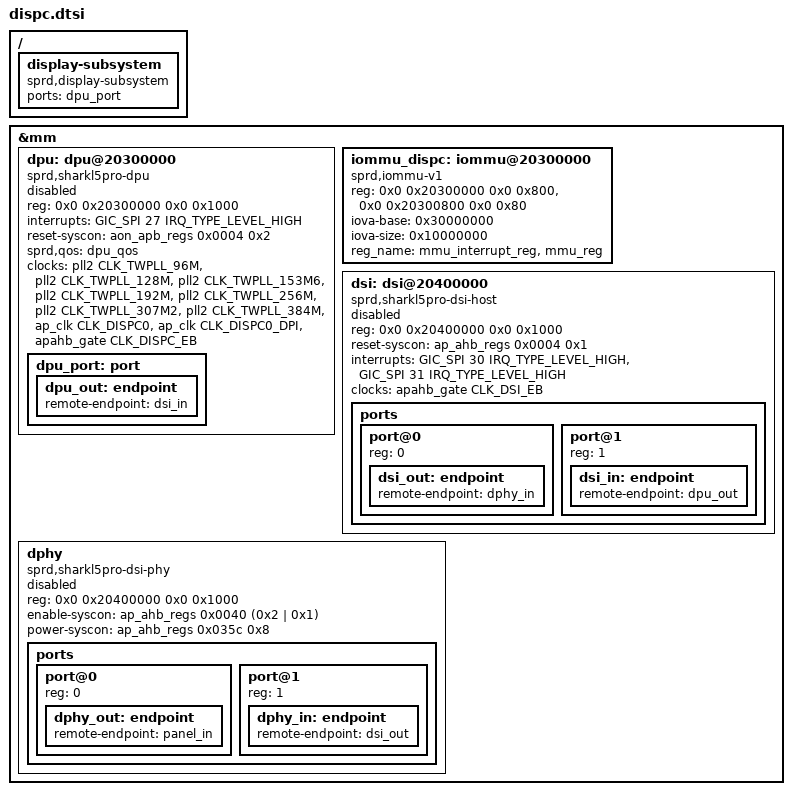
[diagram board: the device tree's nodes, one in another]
&mm {
		dpu: dpu@20300000 {
			compatible = "sprd,sharkl5pro-dpu";
			reg = <0x0 0x20300000 0x0 0x1000>;
			interrupts = <GIC_SPI 27 IRQ_TYPE_LEVEL_HIGH>;

			reset-syscon = <&aon_apb_regs 0x0004 0x2>;
			status = "disabled";
			//iommus = <&iommu_dispc>;
			dpu_port: port {
				dpu_out: endpoint {
					remote-endpoint = <&dsi_in>;
				};
			};
		};

		iommu_dispc: iommu@20300000 {
			compatible = "sprd,iommu-v1";
			reg = <0x0 0x20300000 0x0 0x800>,
					<0x0 0x20300800 0x0 0x80>;
			iova-base = <0x30000000>;
			iova-size = <0x10000000>;
			reg_name = "mmu_interrupt_reg","mmu_reg";
			#iommu-cells = <0>;
		};

		dsi: dsi@20400000 {
			compatible = "sprd,sharkl5pro-dsi-host";
			reg = <0x0 0x20400000 0x0 0x1000>;
			reset-syscon = <&ap_ahb_regs 0x0004 0x1>;
			interrupts = <GIC_SPI 30 IRQ_TYPE_LEVEL_HIGH>,
				<GIC_SPI 31 IRQ_TYPE_LEVEL_HIGH>;
			status = "disabled";

			ports {
				#address-cells = <1>;
				#size-cells = <0>;

				port@0 {
					reg = <0>;
					dsi_out: endpoint {
						remote-endpoint = <&dphy_in>;
					};
				};

				port@1 {
					reg = <1>;
					dsi_in: endpoint {
						remote-endpoint = <&dpu_out>;
					};
				};
			};
		};

		dphy: dphy {
			compatible = "sprd,sharkl5pro-dsi-phy";
			#address-cells = <1>;
			#size-cells = <0>;
			reg = <0x0 0x20400000 0x0 0x1000>;
			enable-syscon = <&ap_ahb_regs 0x0040 (0x2 | 0x1)>;
			power-syscon = <&ap_ahb_regs 0x035c 0x8>;
			status = "disabled";

			/* output port */
			ports {
				#address-cells = <1>;
				#size-cells = <0>;

				port@0 {
					reg = <0>;
					dphy_out: endpoint {
						remote-endpoint = <&panel_in>;
					};
				};

				/* input port*/
				port@1 {
					reg = <1>;
					dphy_in: endpoint {
						remote-endpoint = <&dsi_out>;
					};
				};
			};
		};
};

/ {
	display-subsystem {
		compatible = "sprd,display-subsystem";
		ports = <&dpu_port>;
	};
};


&dpu {
	sprd,qos = <&dpu_qos>;
	clock-names = "clk_src_96m",
			"clk_src_128m",
			"clk_src_153m6",
			"clk_src_192m",
			"clk_src_256m",
			"clk_src_307m2",
			"clk_src_384m",
			"clk_dpu_core",
			"clk_dpu_dpi",
			"clk_ap_ahb_disp_eb";

	clocks = <&pll2 CLK_TWPLL_96M>,
		<&pll2 CLK_TWPLL_128M>,
		<&pll2 CLK_TWPLL_153M6>,
		<&pll2 CLK_TWPLL_192M>,
		<&pll2 CLK_TWPLL_256M>,
		<&pll2 CLK_TWPLL_307M2>,
		<&pll2 CLK_TWPLL_384M>,
		<&ap_clk CLK_DISPC0>,
		<&ap_clk CLK_DISPC0_DPI>,
		<&apahb_gate CLK_DISPC_EB>;
};

&dsi {
	clock-names = "clk_ap_ahb_dsi_eb";
	clocks = <&apahb_gate CLK_DSI_EB>;
};
